# STM32WL5Mxx register map
File version: 1.0
Registers are 32-bit, read-write, reset 0x0 unless marked. A register's access mark holds for its fields unless they carry their own. Offsets are from the block's base; [hi:lo] are bit positions.

## FLASH — FLASH Registers
Base 0x58004000
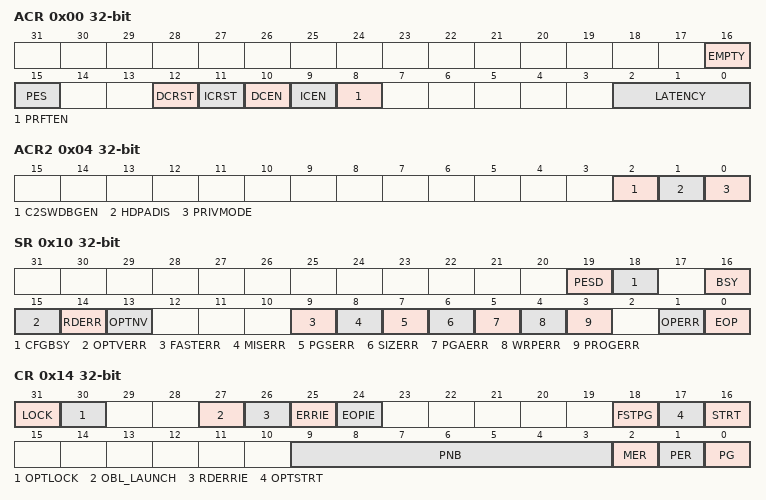
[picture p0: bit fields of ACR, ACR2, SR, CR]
0x00 ACR — FLASH Access control register
  [16] EMPTY — Flash use area empty
  [15] PES — Program/erase suspend request
  [12] DCRST — Data cache reset
  [11] ICRST — Instruction cache reset
  [10] DCEN — Data cache enable
  [9] ICEN — Instruction cache enable
  [8] PRFTEN — Prefetch enable
  [2:0] LATENCY
    0=FLASH Zero wait state; 1=FLASH One wait state; 2=FLASH Two wait states
0x04 ACR2 — FLASH Access control register 2
  [2] C2SWDBGEN — CPU2 Software debug enable
  [1] HDPADIS — Flash User Hide Protection area access disable
  [0] PRIVMODE — CFI privileged mode
0x08 KEYR — FLASH Key register
0x0C OPTKEYR — FLASH Option Key register
0x10 SR — FLASH Status register
  [19] PESD — Programming/erase operation suspended
  [18] CFGBSY — Programming or erase configuration busy
  [16] BSY — Flash Busy
  [15] OPTVERR — Option validity error
  [14] RDERR — PCROP read error
  [13] OPTNV — User option OPTVAL indication
  [9] FASTERR — Fast programming error
  [8] MISERR — Fast programming data miss error
  [7] PGSERR — Programming sequence error
  [6] SIZERR — Size error
  [5] PGAERR — Programming alignment error
  [4] WRPERR — Write protection error
  [3] PROGERR — Programming error
  [1] OPERR — Operation error
  [0] EOP — End of Operation
0x14 CR — FLASH Control register
  [31] LOCK — Flash control register lock
  [30] OPTLOCK — Options lock
  [27] OBL_LAUNCH — Force the option bute loading
  [26] RDERRIE — PCROP read error interrupt enable
  [25] ERRIE — Error interrupt enable
  [24] EOPIE — End of operation interrupt enable
  [18] FSTPG — Fast programming
  [17] OPTSTRT — Options modification start
  [16] STRT — Start an erase operation
  [9:3] PNB — Page number selection mask
  [2] MER — Mass erase
  [1] PER — Page erase
  [0] PG — Flash programming
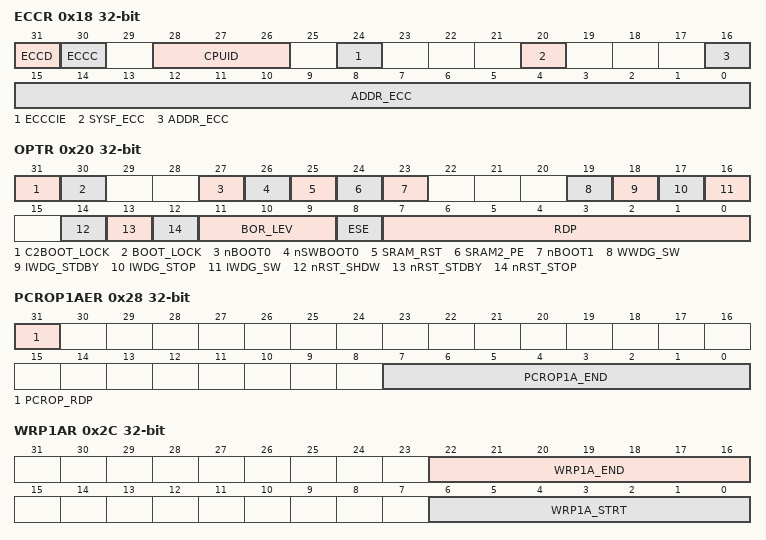
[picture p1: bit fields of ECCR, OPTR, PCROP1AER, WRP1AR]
0x18 ECCR — FLASH ECC register
  [31] ECCD — ECC detection
  [30] ECCC — ECC correction
  [28:26] CPUID — CPU identification
  [24] ECCCIE — ECC correction interrupt enable
  [20] SYSF_ECC — System flash ECC fail
  [16:0] ADDR_ECC — double-word address ECC fail
0x20 OPTR — FLASH Option register
  [31] C2BOOT_LOCK — CPU2 Boot Lock enable option bit
  [30] BOOT_LOCK — CPU1 Boot Lock enable option bit
  [27] nBOOT0 — BOOT0 option bit
  [26] nSWBOOT0 — Software BOOT0
  [25] SRAM_RST — SRAM1 and SRAM2 erase option when system reset
  [24] SRAM2_PE — SRAM2 parity check enable
  [23] nBOOT1 — Boot Configuration
  [19] WWDG_SW — Window watchdog selection
  [18] IWDG_STDBY — Independent watchdog counter option in Standby mode
  [17] IWDG_STOP — Independent watchdog counter option in Stop mode
  [16] IWDG_SW — Independent watchdog selection
  [14] nRST_SHDW — Reset option in Shutdown mode
  [13] nRST_STDBY — Reset option in Standby mode
  [12] nRST_STOP — Reset option in Stop mode
  [11:9] BOR_LEV — BOR reset level mask
  [8] ESE — Security enable
  [7:0] RDP — Read protection level
0x24 PCROP1ASR — FLASH Bank 1 PCROP area A Start address register
  [7:0] PCROP1A_STRT — PCROP area A start offset
0x28 PCROP1AER — FLASH Bank 1 PCROP area A End address register
  [31] PCROP_RDP — PCROP area preserved when RDP level decreased
  [7:0] PCROP1A_END — PCROP area A end offset
0x2C WRP1AR — FLASH Bank 1 WRP area A address register
  [22:16] WRP1A_END — WRP area A end offset
  [6:0] WRP1A_STRT — WRP area A start offset
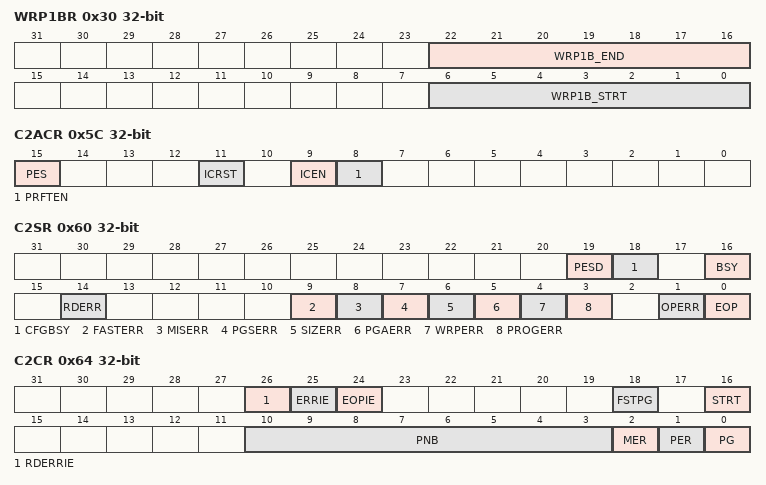
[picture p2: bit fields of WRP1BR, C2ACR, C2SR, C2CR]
0x30 WRP1BR — FLASH Bank 1 WRP area B address register
  [22:16] WRP1B_END — WRP area B end offset
  [6:0] WRP1B_STRT — WRP area B start offset
0x34 PCROP1BSR — FLASH Bank 1 PCROP area B Start address register
  [7:0] PCROP1B_STRT — PCROP area B start offset
0x38 PCROP1BER — FLASH Bank 1 PCROP area B End address register
  [7:0] PCROP1B_END — PCROP area B end offset
0x3C IPCCBR — FLASH IPCC data buffer address
  [13:0] IPCCDBA — IPCC data buffer base address
0x5C C2ACR — FLASH Core MO+ Access Control Register
  [15] PES — CPU2 Program/erase suspend request
  [11] ICRST — CPU2 Instruction cache reset
  [9] ICEN — CPU2 Instruction cache enable
  [8] PRFTEN — CPU2 Prefetch enable
0x60 C2SR — FLASH Core MO+ Status Register
  [19] PESD — CPU2 Programming/erase operation suspended
  [18] CFGBSY — CPU2 Programming or erase configuration busy
  [16] BSY — CPU2 Flash busy
  [14] RDERR — CPU2 PCROP read error
  [9] FASTERR — CPU2 Fast programming error
  [8] MISERR — CPU2 Fast programming data miss error
  [7] PGSERR — CPU2 Programming sequence error
  [6] SIZERR — CPU2 Size error
  [5] PGAERR — CPU2 Programming alignment error
  [4] WRPERR — CPU2 Write protection error
  [3] PROGERR — CPU2 Programming error
  [1] OPERR — CPU2 Operation error
  [0] EOP — CPU2 End of operation
0x64 C2CR — FLASH Core MO+ Control register
  [26] RDERRIE — CPU2 PCROP read error interrupt enable
  [25] ERRIE — CPU2 Error interrupt enable
  [24] EOPIE — CPU2 End of operation interrupt enable
  [18] FSTPG — CPU2 Fast programming
  [16] STRT — CPU2 Start an erase operation
  [10:3] PNB — CPU2 Page number selection mask
  [2] MER — CPU2 Mass erase
  [1] PER — CPU2 Page erase
  [0] PG — CPU2 Flash programming
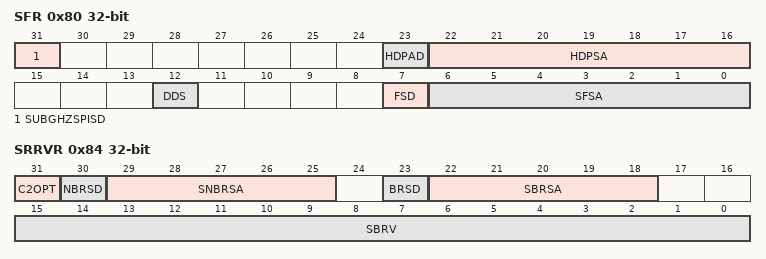
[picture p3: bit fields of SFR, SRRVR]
0x80 SFR — FLASH secure start address
  [31] SUBGHZSPISD
  [23] HDPAD
  [22:16] HDPSA — User Flash Hide Protection Area start address
  [12] DDS
  [7] FSD
  [6:0] SFSA
0x84 SRRVR — FlASH secure SRAM2 start addr and CPU2 reset vector
  [31] C2OPT, [30] NBRSD, [29:25] SNBRSA, [23] BRSD, [22:18] SBRSA, [15:0] SBRV
